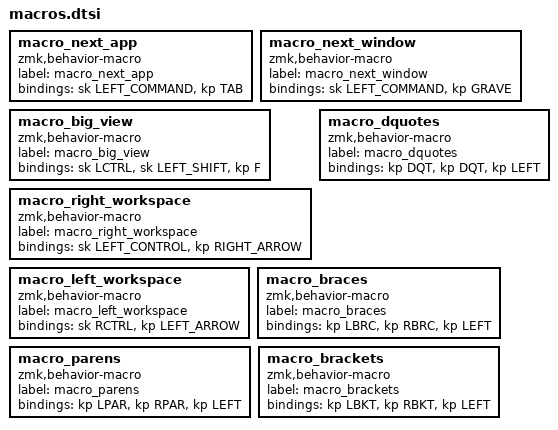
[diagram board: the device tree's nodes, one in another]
macro_next_app: macro_next_app{
compatible = "zmk,behavior-macro";
label = "macro_next_app";
#binding-cells = <0>;
bindings = <&sk LEFT_COMMAND>, <&kp TAB>;
};
macro_next_window: macro_next_window{
compatible = "zmk,behavior-macro";
label = "macro_next_window";
#binding-cells = <0>;
bindings = <&sk LEFT_COMMAND>, <&kp GRAVE>;
};
macro_big_view: macro_big_view{
compatible = "zmk,behavior-macro";
label = "macro_big_view";
#binding-cells = <0>;
bindings = <&sk LCTRL>, <&sk LEFT_SHIFT>, <&kp F>;
};
macro_right_workspace: macro_right_workspace{
compatible = "zmk,behavior-macro";
label = "macro_right_workspace";
#binding-cells = <0>;
bindings = <&sk LEFT_CONTROL>, <&kp RIGHT_ARROW>;
};
macro_left_workspace: macro_left_workspace{
compatible = "zmk,behavior-macro";
label = "macro_left_workspace";
#binding-cells = <0>;
bindings = <&sk RCTRL>, <&kp LEFT_ARROW>;
};
macro_dquotes: macro_dquotes{
compatible = "zmk,behavior-macro";
label = "macro_dquotes";
#binding-cells = <0>;
bindings = <&kp DQT>, <&kp DQT>, <&kp LEFT>;
};
macro_braces: macro_braces{
compatible = "zmk,behavior-macro";
label = "macro_braces";
#binding-cells = <0>;
bindings = <&kp LBRC>, <&kp RBRC>, <&kp LEFT>;
};
macro_parens: macro_parens{
compatible = "zmk,behavior-macro";
label = "macro_parens";
#binding-cells = <0>;
bindings = <&kp LPAR>, <&kp RPAR>, <&kp LEFT>;
};
macro_brackets: macro_brackets{
compatible = "zmk,behavior-macro";
label = "macro_brackets";
#binding-cells = <0>;
bindings = <&kp LBKT>, <&kp RBKT>, <&kp LEFT>;
};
